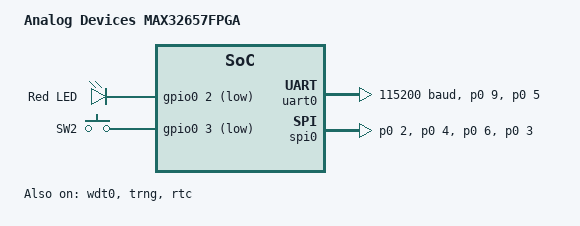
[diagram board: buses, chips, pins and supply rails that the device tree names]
/*
 * Copyright (c) 2024 Analog Devices, Inc.
 *
 * SPDX-License-Identifier: Apache-2.0
 */

#include <adi/max32/max32657-pinctrl.dtsi>
#include <zephyr/dt-bindings/gpio/gpio.h>
#include <zephyr/dt-bindings/gpio/adi-max32-gpio.h>

/ {
	model = "Analog Devices MAX32657FPGA";
	compatible = "adi,max32657fpga";

	chosen {
		zephyr,console = &uart0;
		zephyr,shell-uart = &uart0;
	};

	leds {
		compatible = "gpio-leds";
		led1: led_1 {
			gpios = <&gpio0 2 GPIO_ACTIVE_LOW>;
			label = "Red LED";
		};
	};

	buttons {
		compatible = "gpio-keys";
		pb1: pb1 {
			gpios = <&gpio0 3 (GPIO_PULL_UP | GPIO_ACTIVE_LOW)>;
			label = "SW2";
		};
	};

	/* These aliases are provided for compatibility with samples */
	aliases {
		led0 = &led1;
		sw0 = &pb1;
		watchdog0 = &wdt0;
		rtc = &rtc;
	};
};

&uart0 {
	pinctrl-0 = <&uart0_tx_p0_9 &uart0_rx_p0_5>;
	pinctrl-names = "default";
	current-speed = <115200>;
	data-bits = <8>;
	parity = "none";
	status = "okay";
};

&clk_ipo {
	status = "okay";
};

/*
 * ERTCO requires for RTC
 */
&clk_ertco {
	status = "okay";
};

&gpio0 {
	status = "okay";
};

&wdt0 {
	status = "okay";
};

&trng {
	status = "okay";
};

&rtc {
	status = "okay";
	alarms-count = <1>;
};

&spi0 {
	status = "okay";
	pinctrl-0 = <&spi0_mosi_p0_2 &spi0_miso_p0_4 &spi0_sck_p0_6 &spi0_ss0_p0_3>;
	pinctrl-names = "default";
};
